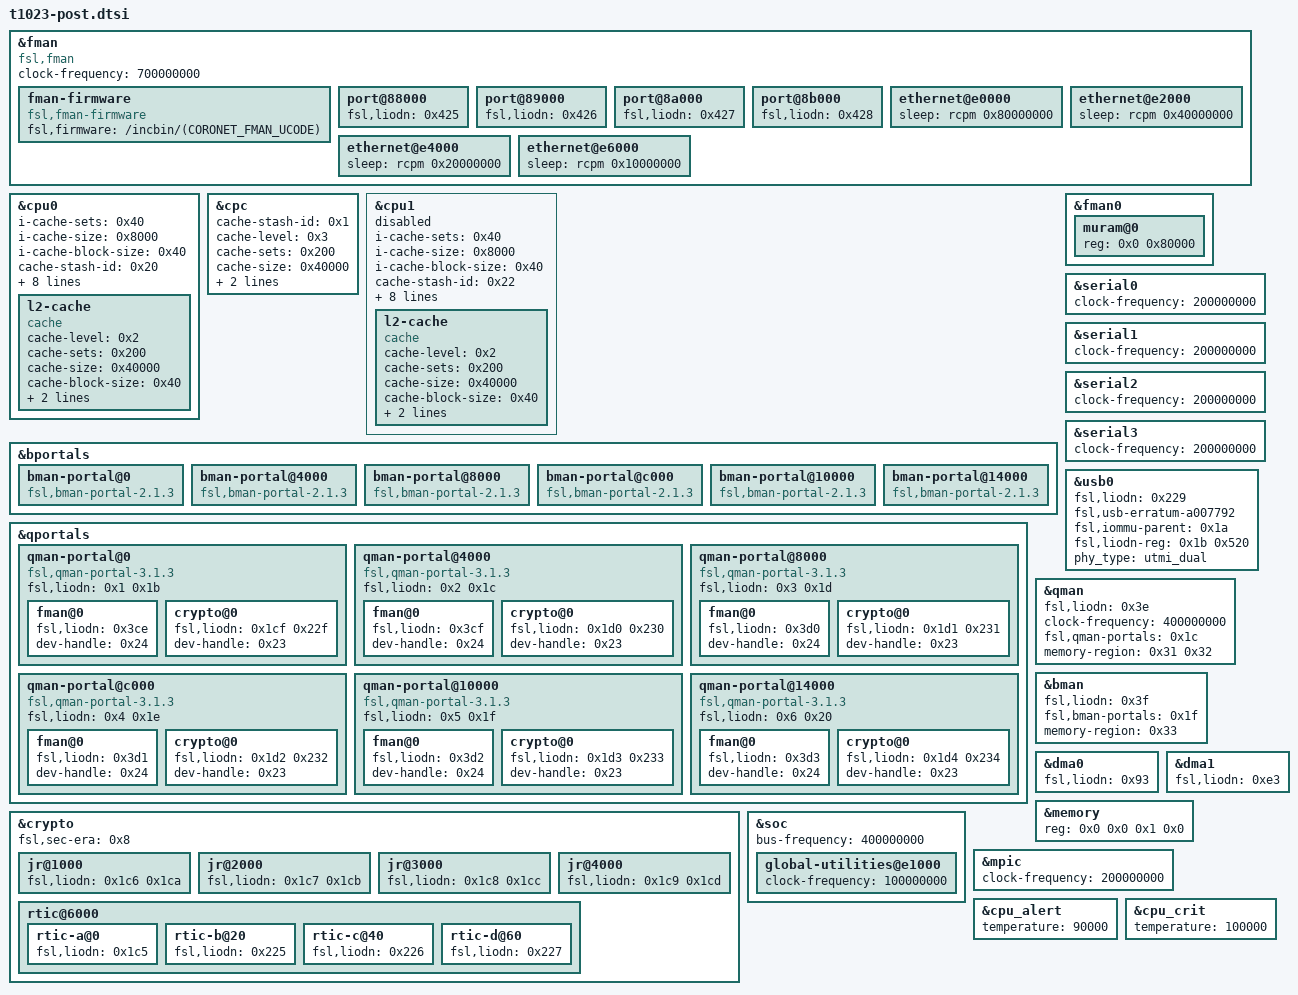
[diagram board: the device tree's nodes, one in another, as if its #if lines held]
/**
*  The purpose with this file is to not do any static changes
*  to the device-tree in runtime (as Freescale do with U-boot)
*
*  Keep this file free from Westermo specific changes,
*  this is reserved for "U-boot"-modifications.
*/

&fman {
        compatible = "fsl,fman", "simple-bus";
        clock-frequency = <700000000>;

#ifdef CORONET_FMAN_UCODE
	fman-firmware {
		fsl,firmware = /incbin/(CORONET_FMAN_UCODE);
		compatible = "fsl,fman-firmware";
	};
#endif
        port@88000 {
		fsl,liodn = <0x425>;
        };
        port@89000 {
		fsl,liodn = <0x426>;
        };
	port@8a000 {
		fsl,liodn = <0x427>;
        };
        port@8b000 {
		fsl,liodn = <0x428>;
        };
        ethernet@e0000 {
                sleep = <&rcpm 0x80000000>;
        };
        ethernet@e2000 {
		sleep = <&rcpm 0x40000000>;
	};
        ethernet@e4000 {
		sleep = <&rcpm 0x20000000>;
	};
        ethernet@e6000 {
                sleep = <&rcpm 0x10000000>;
        };
};
&cpu0 {
        i-cache-sets = <0x40>;
        i-cache-size = <0x8000>;
        i-cache-block-size = <0x40>;
        cache-stash-id = <0x20>;
        d-cache-sets = <0x40>;
        d-cache-size = <0x8000>;
        d-cache-block-size = <0x40>;
        enable-method = "spin-table";
        cpu-release-addr = <0x0 0x7fef4100>;
        status = "okay";
        clock-frequency = "SrN";
        bus-frequency = <0x17d78400>;
        timebase-frequency = <0x17d7840>;
        l2-cache {
                compatible = "cache";
                cache-level = <0x2>;
                cache-sets = <0x200>;
                cache-size = <0x40000>;
                cache-block-size = <0x40>;
                cache-unified;
                cache-stash-id = <0x21>;
        };
};
&cpc {
        cache-stash-id = <0x1>;
        cache-level = <0x3>;
        cache-sets = <0x200>;
        cache-size = <0x40000>;
        cache-block-size = <0x40>;
        cache-unified;
};
&cpu1 {
        i-cache-sets = <0x40>;
        i-cache-size = <0x8000>;
        i-cache-block-size = <0x40>;
        cache-stash-id = <0x22>;
        d-cache-sets = <0x40>;
        d-cache-size = <0x8000>;
        d-cache-block-size = <0x40>;
        enable-method = "spin-table";
        cpu-release-addr = <0x0 0x7fef4140>;
        status = "disabled";
        clock-frequency = "SrN";
        bus-frequency = <0x17d78400>;
        timebase-frequency = <0x17d7840>;
        l2-cache {
                compatible = "cache";
                cache-level = <0x2>;
                cache-sets = <0x200>;
                cache-size = <0x40000>;
                cache-block-size = <0x40>;
                cache-unified;
                cache-stash-id = <0x23>;
        };
};
&bportals {
        bman-portal@0 {
                compatible = "fsl,bman-portal-2.1.3", "fsl,bman-portal";
        };
        bman-portal@4000 {
                compatible = "fsl,bman-portal-2.1.3", "fsl,bman-portal";
        };
        bman-portal@8000 {
                compatible = "fsl,bman-portal-2.1.3", "fsl,bman-portal";
        };
        bman-portal@c000 {
                compatible = "fsl,bman-portal-2.1.3", "fsl,bman-portal";
        };
        bman-portal@10000 {
                compatible = "fsl,bman-portal-2.1.3", "fsl,bman-portal";
        };
        bman-portal@14000 {
                compatible = "fsl,bman-portal-2.1.3", "fsl,bman-portal";
        };
};
&qportals {
        qman-portal@0 {
                fsl,liodn = <0x1 0x1b>;
                compatible = "fsl,qman-portal-3.1.3", "fsl,qman-portal";

                fman@0 {
                        fsl,liodn = <0x3ce>;
                        dev-handle = <0x24>;
                };

                crypto@0 {
                        fsl,liodn = <0x1cf 0x22f>;
                        dev-handle = <0x23>;
                };
        };

        qman-portal@4000 {
                fsl,liodn = <0x2 0x1c>;
                compatible = "fsl,qman-portal-3.1.3", "fsl,qman-portal";

                fman@0 {
                        fsl,liodn = <0x3cf>;
                        dev-handle = <0x24>;
                };

                crypto@0 {
                        fsl,liodn = <0x1d0 0x230>;
                        dev-handle = <0x23>;
                };

        };

        qman-portal@8000 {
                fsl,liodn = <0x3 0x1d>;
                compatible = "fsl,qman-portal-3.1.3", "fsl,qman-portal";
                fman@0 {
                        fsl,liodn = <0x3d0>;
                        dev-handle = <0x24>;
                };

                crypto@0 {
                        fsl,liodn = <0x1d1 0x231>;
                        dev-handle = <0x23>;
                };
        };

        qman-portal@c000 {
                fsl,liodn = <0x4 0x1e>;
                compatible = "fsl,qman-portal-3.1.3", "fsl,qman-portal";

                fman@0 {
                        fsl,liodn = <0x3d1>;
                        dev-handle = <0x24>;
                };

                crypto@0 {
                        fsl,liodn = <0x1d2 0x232>;
                        dev-handle = <0x23>;
                };
        };

        qman-portal@10000 {
                fsl,liodn = <0x5 0x1f>;
                compatible = "fsl,qman-portal-3.1.3", "fsl,qman-portal";

                fman@0 {
                        fsl,liodn = <0x3d2>;
                        dev-handle = <0x24>;
                };

                crypto@0 {
                        fsl,liodn = <0x1d3 0x233>;
                        dev-handle = <0x23>;
                };
        };

        qman-portal@14000 {
                fsl,liodn = <0x6 0x20>;
                compatible = "fsl,qman-portal-3.1.3", "fsl,qman-portal";
                fman@0 {
                        fsl,liodn = <0x3d3>;
                        dev-handle = <0x24>;
                };

                crypto@0 {
                        fsl,liodn = <0x1d4 0x234>;
                        dev-handle = <0x23>;
                };

        };
};


&fman0 {
        muram@0 {
                reg = <0x0 0x80000>;
        };
};

&serial0 {
         clock-frequency = <200000000>;
};

&serial1 {
         clock-frequency = <200000000>;
};

&serial2 {
         clock-frequency = <200000000>;
};

&serial3 {
         clock-frequency = <200000000>;
};

&usb0 {
        fsl,liodn = <0x229>;
        fsl,usb-erratum-a007792;
        fsl,iommu-parent = <0x1a>;
        fsl,liodn-reg = <0x1b 0x520>;
        phy_type = "utmi_dual";
};
&crypto {
        fsl,sec-era = <0x8>;
        jr@1000 {
                fsl,liodn = <0x1c6 0x1ca>;
        };
        jr@2000 {
                fsl,liodn = <0x1c7 0x1cb>;
        };
        jr@3000 {
                fsl,liodn = <0x1c8 0x1cc>;
        };
        jr@4000 {
                fsl,liodn = <0x1c9 0x1cd>;
        };
        rtic@6000 {
                rtic-a@0 {
                        fsl,liodn = <0x1c5>;
                };
                rtic-b@20 {
                        fsl,liodn = <0x225>;
                };
                rtic-c@40 {
                        fsl,liodn = <0x226>;
                };
                rtic-d@60 {
                        fsl,liodn = <0x227>;
                };
        };
};
&qman {
        fsl,liodn = <0x3e>;
        clock-frequency = <400000000>;
        
        fsl,qman-portals = <0x1c>;
        memory-region = <0x31 0x32>;
};

&bman {
        fsl,liodn = <0x3f>;
        fsl,bman-portals = <0x1f>;
        memory-region = <0x33>;
};

&dma0 {
	fsl,liodn = <0x93>;
};

&dma1 {
        fsl,liodn = <0xe3>;
};

&memory {
        reg = <0x0 0x0 0x1 0x0>;
};

&soc {
        bus-frequency = <400000000>;
        global-utilities@e1000 {
                clock-frequency = <100000000>;
        };
};

&mpic {
        clock-frequency = <200000000>;
};

&cpu_alert {
        temperature = <90000>;
};

&cpu_crit {
        temperature = <100000>;
};
